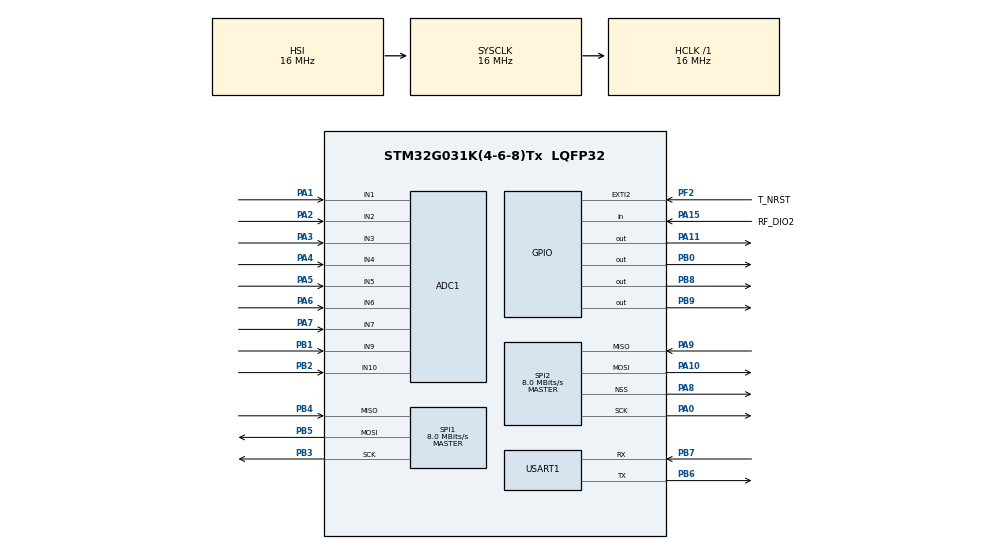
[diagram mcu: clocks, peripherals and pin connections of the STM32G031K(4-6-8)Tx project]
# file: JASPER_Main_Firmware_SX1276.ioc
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ADC1.Channel-0\#ChannelRegularConversion=ADC_CHANNEL_4
ADC1.NbrOfConversionFlag=1
ADC1.Rank-0\#ChannelRegularConversion=1
ADC1.SamplingTime-0\#ChannelRegularConversion=ADC_SAMPLINGTIME_COMMON_1
ADC1.SelectedChannel=ADC_CHANNEL_1|ADC_CHANNEL_2|ADC_CHANNEL_3|ADC_CHANNEL_4|ADC_CHANNEL_5|ADC_CHANNEL_6|ADC_CHANNEL_7|ADC_CHANNEL_9|ADC_CHANNEL_10
ADC1.master=1
Mcu.Family=STM32G0
Mcu.Name=STM32G031K(4-6-8)Tx
Mcu.Package=LQFP32
PA0.Mode=Full_Duplex_Master
PA0.Signal=SPI2_SCK
PA1.Mode=IN1
PA1.Signal=ADC1_IN1
PA10.Mode=Full_Duplex_Master
PA10.Signal=SPI2_MOSI
PA11\ [PA9].Signal=GPIO_Output
PA13.Mode=Serial_Wire
PA13.Signal=SYS_SWDIO
PA14-BOOT0.Mode=Serial_Wire
PA14-BOOT0.Signal=SYS_SWCLK
PA15.GPIO_Label=RF_DIO2
PA15.Signal=GPIO_Input
PA2.Mode=IN2
PA2.Signal=ADC1_IN2
PA3.Mode=IN3
PA3.Signal=ADC1_IN3
PA4.Mode=IN4
PA4.Signal=ADC1_IN4
PA5.Mode=IN5
PA5.Signal=ADC1_IN5
PA6.Mode=IN6
PA6.Signal=ADC1_IN6
PA7.Mode=IN7
PA7.Signal=ADC1_IN7
PA8.Mode=NSS_Signal_Hard_Output
PA8.Signal=SPI2_NSS
PA9.Mode=Full_Duplex_Master
PA9.Signal=SPI2_MISO
PB0.Signal=GPIO_Output
PB1.Mode=IN9
PB1.Signal=ADC1_IN9
PB2.Mode=IN10
PB2.Signal=ADC1_IN10
PB3.Mode=Full_Duplex_Master
PB3.Signal=SPI1_SCK
PB4.Mode=Full_Duplex_Master
PB4.Signal=SPI1_MISO
PB5.Mode=Full_Duplex_Master
PB5.Signal=SPI1_MOSI
PB6.Mode=Asynchronous
PB6.Signal=USART1_TX
PB7.Mode=Asynchronous
PB7.Signal=USART1_RX
PB8.Signal=GPIO_Output
PB9.Signal=GPIO_Output
PC14-OSC32_IN\ (PC14).Mode=LSE-External-Oscillator
PC14-OSC32_IN\ (PC14).Signal=RCC_OSC32_IN
PC15-OSC32_OUT\ (PC15).Mode=LSE-External-Oscillator
PC15-OSC32_OUT\ (PC15).Signal=RCC_OSC32_OUT
PF2\ -\ NRST.GPIO_Label=T_NRST
PF2\ -\ NRST.Signal=GPXTI2
ProjectManager.HeapSize=0x200
ProjectManager.StackSize=0x400
ProjectManager.TargetToolchain=STM32CubeIDE
RCC.AHBFreq_Value=16000000
RCC.CortexFreq_Value=16000000
RCC.EXTERNAL_CLOCK_VALUE=12288000
RCC.HCLKFreq_Value=16000000
RCC.HSE_VALUE=8000000
RCC.HSI_VALUE=16000000
RCC.SYSCLKFreq_VALUE=16000000
RCC.VCOOutputFreq_Value=128000000
SPI1.BaudRatePrescaler=SPI_BAUDRATEPRESCALER_2
SPI1.CalculateBaudRate=8.0 MBits/s
SPI1.Direction=SPI_DIRECTION_2LINES
SPI1.Mode=SPI_MODE_MASTER
SPI1.VirtualType=VM_MASTER
SPI2.CalculateBaudRate=8.0 MBits/s
SPI2.Direction=SPI_DIRECTION_2LINES
SPI2.Mode=SPI_MODE_MASTER
SPI2.VirtualNSS=VM_NSSHARD
SPI2.VirtualType=VM_MASTER
USART1.VirtualMode-Asynchronous=VM_ASYNC
board=NUCLEO-G031K8

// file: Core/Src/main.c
/* USER CODE BEGIN Header */
/**
  ******************************************************************************
  * @file           : main.c
  * @brief          : Main program body
  ******************************************************************************
  * @attention
  *
  * Copyright (c) 2023 STMicroelectronics.
  * All rights reserved.
  *
  * This software is licensed under terms that can be found in the LICENSE file
  * in the root directory of this software component.
  * If no LICENSE file comes with this software, it is provided AS-IS.
  *
  ******************************************************************************
  */
/* USER CODE END Header */
#include "main.h"
#include "adc.h"
#include "spi.h"
#include "usart.h"
#include "gpio.h"

/* USER CODE BEGIN Includes */
#include "all_includes.h"
/* USER CODE END Includes */

void SystemClock_Config(void);

int main(void)
{

  /* MCU Configuration--------------------------------------------------------*/

  /* Reset of all peripherals, Initializes the Flash interface and the Systick. */
  HAL_Init();

  /* Configure the system clock */
  SystemClock_Config();

  /* Initialize all configured peripherals */
  MX_GPIO_Init();
  MX_ADC1_Init();
  MX_SPI2_Init();
  MX_USART1_UART_Init();
  MX_SPI1_Init();
  /* USER CODE BEGIN 2 */

	debug_println("INFO: Booting JASPER_Main_Firmware_SX1276");
	HAL_Delay(250);

	run_once_on_boot();

  /* USER CODE END 2 */

  /* Infinite loop */
  /* USER CODE BEGIN WHILE */
	long unsigned int superloop_count = 0;
  while (1)
  {

	  const uint8_t msg1[255];
	  sprintf(msg1, "INFO: Starting superloop from JASPER_Main_Firmware_SX1276 #%lu\n", superloop_count++);
	  HAL_UART_Transmit(&huart1, msg1, strlen(msg1), 120);
	  	HAL_Delay(250);

	  	main_loop();
	  	// TODO: LED blink
    /* USER CODE END WHILE */

  }
}

void SystemClock_Config(void)
{
  RCC_OscInitTypeDef RCC_OscInitStruct = {0};
  RCC_ClkInitTypeDef RCC_ClkInitStruct = {0};

  /** Configure the main internal regulator output voltage
  */
  HAL_PWREx_ControlVoltageScaling(PWR_REGULATOR_VOLTAGE_SCALE1);

  /** Initializes the RCC Oscillators according to the specified parameters
  * in the RCC_OscInitTypeDef structure.
  */
  RCC_OscInitStruct.OscillatorType = RCC_OSCILLATORTYPE_HSI;
  RCC_OscInitStruct.HSIState = RCC_HSI_ON;
  RCC_OscInitStruct.HSIDiv = RCC_HSI_DIV1;
  RCC_OscInitStruct.HSICalibrationValue = RCC_HSICALIBRATION_DEFAULT;
  RCC_OscInitStruct.PLL.PLLState = RCC_PLL_NONE;
  if (HAL_RCC_OscConfig(&RCC_OscInitStruct) != HAL_OK)
  {
    Error_Handler();
  }

  /** Initializes the CPU, AHB and APB buses clocks
  */
  RCC_ClkInitStruct.ClockType = RCC_CLOCKTYPE_HCLK|RCC_CLOCKTYPE_SYSCLK
                              |RCC_CLOCKTYPE_PCLK1;
  RCC_ClkInitStruct.SYSCLKSource = RCC_SYSCLKSOURCE_HSI;
  RCC_ClkInitStruct.AHBCLKDivider = RCC_SYSCLK_DIV1;
  RCC_ClkInitStruct.APB1CLKDivider = RCC_HCLK_DIV1;

  if (HAL_RCC_ClockConfig(&RCC_ClkInitStruct, FLASH_LATENCY_0) != HAL_OK)
  {
    Error_Handler();
  }
}

void Error_Handler(void)
{
  __disable_irq();
  while (1)
  {
  }
}
